AUTOSAR XML (schema 4-3-1)
standard types defined: Double, SInt8, float64, sint8
package /pkg/swc
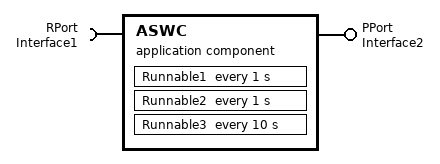
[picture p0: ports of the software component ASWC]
  application sw component type ASWC
    require port RPort: required-interface=Interface1
      required-com-specs:
        {data-element=Interface1/DE1, alive-timeout=60, init-value=constant-reference={short-label=DefaultInitValue_Double, constant=DefaultInitValue_Double}}
        {data-element=Interface1/DE2, alive-timeout=60, init-value=constant-reference={short-label=DefaultInitValu_036fab392deee624, constant=DefaultInitValu_036fab392deee624}}
    provide port PPort: provided-interface=Interface2
      provided-com-specs:
        {data-element=Interface2/DE1, init-value=constant-reference={short-label=DefaultInitValue_SInt8, constant=DefaultInitValue_SInt8}}
        {data-element=Interface2/DE2, init-value=constant-reference={short-label=DefaultInitValue_SInt8, constant=DefaultInitValue_SInt8}}
        {data-element=DE3, init-value=constant-reference={short-label=DefaultInitValue_SInt8, constant=DefaultInitValue_SInt8}}
        {data-element=DE4, init-value=constant-reference={short-label=DefaultInitValue_Double, constant=DefaultInitValue_Double}}
    behavior IB: handle-termination-and-restart=NO-SUPPORT
      timing event Event_t_1tic_A: start-on-event=Runnable1, period=1
      timing event Event_t_1tic_B: start-on-event=Runnable2, period=1
      timing event Event_t_10tic: start-on-event=Runnable3, period=10
      implicit-inter-runnable-variables:
        4 x data, all with category=VALUE, sw-calibration-access=READ-ONLY:
          IRV1: type=Double, init-value=constant-reference={short-label=DefaultInitValue_Double, constant=DefaultInitValue_Double}
          IRV2: type=Double, init-value=constant-reference={short-label=DefaultInitValue_Double, constant=DefaultInitValue_Double}
          IRV3: type=SInt8, init-value=constant-reference={short-label=DefaultInitValue_SInt8, constant=DefaultInitValue_SInt8}
          IRV4: type=Double, init-value=constant-reference={short-label=DefaultInitValue_Double, constant=DefaultInitValue_Double}
      4 x runnable:
        Runnable_Init
        Runnable1
          data-read-access:
            access IN_RPort_DE1: accessed-variable=RPort.DE1
          data-write-access:
            access OUT_PPort_DE1: accessed-variable=PPort.DE1
          read-local-variables:
            access RV_IRV3: accessed-variable=IRV3
          written-local-variables:
            access WV_IRV1: accessed-variable=IRV1
        Runnable2
          data-write-access:
            access OUT_PPort_DE3: accessed-variable=PPort.DE3
            access OUT_PPort_DE4: accessed-variable=PPort.DE4
          read-local-variables:
            access RV_IRV1: accessed-variable=IRV1
            access RV_IRV2: accessed-variable=IRV2
          written-local-variables:
            access WV_IRV4: accessed-variable=IRV4
        Runnable3
          data-read-access:
            access IN_RPort_DE2: accessed-variable=RPort.DE2
          data-write-access:
            access OUT_PPort_DE2: accessed-variable=PPort.DE2
          read-local-variables:
            access RV_IRV4: accessed-variable=IRV4
          written-local-variables:
            access WV_IRV2: accessed-variable=IRV2
            access WV_IRV3: accessed-variable=IRV3
package /pkg/if
  sender receiver interface Interface1
    data DE1: category=VALUE, sw-calibration-access=READ-ONLY, type=Double
    data DE2: category=ARRAY, sw-calibration-access=READ-ONLY, type=rt_Array_Double_2
  sender receiver interface Interface2
    4 x data, all with category=VALUE, sw-calibration-access=READ-ONLY:
      DE{1..3}: type=SInt8
      DE4: type=Double
package /pkg/dt
  impl type rt_Array_Double_2: category=ARRAY
    element rt_Array_Double_2: array-size=2, array-size-semantics=FIXED-SIZE, implementation-data-type=Double
  impl type rt_Array_SInt8_2: category=ARRAY
    element rt_Array_SInt8_2: array-size=2, array-size-semantics=FIXED-SIZE, implementation-data-type=SInt8
package /pkg/dt/Ground
  4 x constant specification:
    DefaultInitValue_Double: value-spec=0
    DefaultInitValu_036fab392deee624: value-spec=[{short-label=DefaultInitValu_d172891e92bde674, constant=DefaultInitValue_Double}, {short-label=DefaultInitValu_2d898f9704c2f030, constant=DefaultInitValue_Double}]
    DefaultInitValue_SInt8: value-spec=0
    DefaultInitValu_33c01c7d02936bc6: value-spec=[{short-label=DefaultInitValu_ea84cfedb01feb42, constant=DefaultInitValue_SInt8}, {short-label=DefaultInitValu_5f83b4901e9f9ad9, constant=DefaultInitValue_SInt8}]
package /pkg/imp
  swc implementation ASWC_impl: programming-language=C, sw-version=4.20.1, used-code-generator=Embedded Coder 7.6 (R2021a) 14-Nov-2020, vendor-id=0, behavior=IB
    code-descriptors:
      code Code
        artifact-descriptors:
          short-label=autosar_swc_expfcns_c, category=SWSRC
          short-label=autosar_swc_expfcns_h, category=SWHDR
          short-label=rtwtypes_h, category=SWHDR
    resource consumption RsrcCons_autosar_swc_expfcns
package /Timing
  swc timing ASWC_timing: behavior=IB
    timing-requirements:
      execution order constraint EOC
        ordered-elements:
          eoc executable entity ref Runnable1: executable=Runnable1, successor=Runnable2
          eoc executable entity ref Runnable2: executable=Runnable2, successor=Runnable3
          eoc executable entity ref Runnable3: executable=Runnable3
